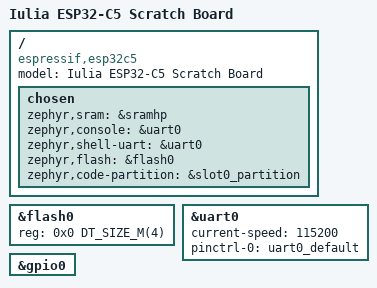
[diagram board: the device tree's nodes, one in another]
/dts-v1/;

#include <espressif/esp32c5/esp32c5_wroom_n8r8.dtsi>
#include "iulia_esp32c5_scratch_hpcore-pinctrl.dtsi"
#include "partitions_0x2000_default_4M.dtsi"

/ {
    model = "Iulia ESP32-C5 Scratch Board";
    compatible = "espressif,esp32c5";

    chosen {
        zephyr,sram = &sramhp;
        zephyr,console = &uart0;
        zephyr,shell-uart = &uart0;
        zephyr,flash = &flash0;
        zephyr,code-partition = &slot0_partition;
    };
};

&flash0 {
    reg = <0x0 DT_SIZE_M(4)>;
    ranges = <0x0 0x0 DT_SIZE_M(4)>;
};

&uart0 {
    status = "okay";
    current-speed = <115200>;
    pinctrl-0 = <&uart0_default>;
    pinctrl-names = "default";
};

&gpio0 {
    status = "okay";
};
